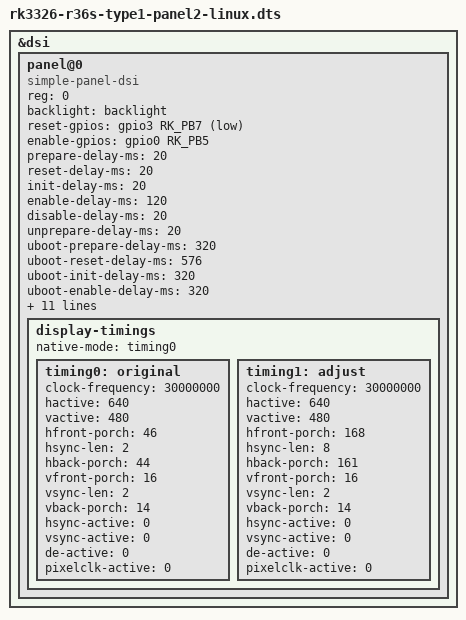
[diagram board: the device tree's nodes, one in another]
// SPDX-License-Identifier: (GPL-2.0+ OR MIT)
/*
* Copyright (c) 2025 kk&lcdyk
*
* R36S Clone掌机 种类1
*
*/

/dts-v1/;
#include "rk3326-r36s-type1-panel1-linux.dts"

&dsi {
	status = "okay";
	
	panel@0 {
		compatible = "simple-panel-dsi";
		reg = <0>;
		/* pwm1 backlight */
		backlight = <&backlight>;
		/* LCD reset gpio GPIO3.B7 */
		reset-gpios = <&gpio3 RK_PB7 GPIO_ACTIVE_LOW>;
		/* LCD reset gpio GPIO0.B5 */
		enable-gpios = <&gpio0 RK_PB5 GPIO_ACTIVE_HIGH>;
		prepare-delay-ms = <20>;
		reset-delay-ms = <20>;
		init-delay-ms = <20>;
		enable-delay-ms = <120>;
		disable-delay-ms = <20>;
		unprepare-delay-ms = <20>;
		uboot-prepare-delay-ms = <320>;
		uboot-reset-delay-ms = <576>;
		uboot-init-delay-ms = <320>;
		uboot-enable-delay-ms = <320>;
		uboot-disable-delay-ms = <320>;
		uboot-unprepare-delay-ms = <20>;
		width-mm = <153>;
		height-mm = <85>;
		dsi,flags  = <(MIPI_DSI_MODE_VIDEO |
		MIPI_DSI_MODE_VIDEO_BURST |
		MIPI_DSI_MODE_LPM |
		MIPI_DSI_MODE_EOT_PACKET)>;
		dsi,format = <MIPI_DSI_FMT_RGB888>;
		dsi,lanes = <4>;
		panel-init-sequence = [15 00 02 ff 30 15 00 02 ff 52 15 00 02 ff 01 15 00 02 e3 00 15 00 02 25 10 15 00 02 28 6f 15 00 02 29 01 15 00 02 2a df 15 00 02 2c 22 15 00 02 c3 0f 15 00 02 37 9c 15 00 02 38 a7 15 00 02 39 41 15 00 02 80 20 15 00 02 91 67 15 00 02 92 67 15 00 02 a0 55 15 00 02 a1 50 15 00 02 a3 58 15 00 02 a4 9c 15 00 02 a7 02 15 00 02 a8 01 15 00 02 a9 21 15 00 02 aa fc 15 00 02 ab 28 15 00 02 ac 06 15 00 02 ad 06 15 00 02 ae 06 15 00 02 af 03 15 00 02 b0 08 15 00 02 b1 26 15 00 02 b2 28 15 00 02 b3 28 15 00 02 b4 03 15 00 02 b5 08 15 00 02 b6 26 15 00 02 b7 08 15 00 02 b8 26 15 00 02 c0 00 15 00 02 c1 00 15 00 02 c2 00 15 00 02 ff 30 15 00 02 ff 52 15 00 02 ff 02 15 00 02 b0 02 15 00 02 d0 02 15 00 02 b1 0f 15 00 02 d1 10 15 00 02 b2 11 15 00 02 d2 12 15 00 02 b3 32 15 00 02 d3 33 15 00 02 b4 36 15 00 02 d4 36 15 00 02 b5 3c 15 00 02 d5 3c 15 00 02 b6 20 15 00 02 d6 20 15 00 02 b7 3e 15 00 02 d7 3e 15 00 02 b8 0e 15 00 02 d8 0d 15 00 02 b9 05 15 00 02 d9 05 15 00 02 ba 11 15 00 02 da 12 15 00 02 bb 11 15 00 02 db 11 15 00 02 bc 13 15 00 02 dc 14 15 00 02 bd 14 15 00 02 dd 14 15 00 02 be 16 15 00 02 de 18 15 00 02 bf 0e 15 00 02 df 0f 15 00 02 c0 17 15 00 02 e0 17 15 00 02 c1 07 15 00 02 e1 08 15 00 02 ff 30 15 00 02 ff 52 15 00 02 ff 03 15 00 02 08 8a 15 00 02 09 8b 15 00 02 30 00 15 00 02 31 00 15 00 02 32 00 15 00 02 33 00 15 00 02 34 61 15 00 02 35 d4 15 00 02 36 24 15 00 02 37 03 15 00 02 40 86 15 00 02 41 87 15 00 02 42 84 15 00 02 43 85 15 00 02 44 11 15 00 02 45 de 15 00 02 46 dd 15 00 02 47 11 15 00 02 48 e0 15 00 02 49 df 15 00 02 50 82 15 00 02 51 83 15 00 02 52 80 15 00 02 53 81 15 00 02 54 11 15 00 02 55 e2 15 00 02 56 e1 15 00 02 57 11 15 00 02 58 e4 15 00 02 59 e3 15 00 02 82 0f 15 00 02 83 0f 15 00 02 84 00 15 00 02 85 0f 15 00 02 86 0f 15 00 02 87 0e 15 00 02 88 0e 15 00 02 89 06 15 00 02 8a 06 15 00 02 8b 07 15 00 02 8c 07 15 00 02 8d 04 15 00 02 8e 04 15 00 02 8f 05 15 00 02 90 05 15 00 02 98 0f 15 00 02 99 0f 15 00 02 9a 00 15 00 02 9b 0f 15 00 02 9c 0f 15 00 02 9d 0e 15 00 02 9e 0e 15 00 02 9f 06 15 00 02 a0 06 15 00 02 a1 07 15 00 02 a2 07 15 00 02 a3 04 15 00 02 a4 04 15 00 02 a5 05 15 00 02 a6 05 15 00 02 e0 02 15 00 02 e1 52 15 00 02 ff 30 15 00 02 ff 52 15 00 02 ff 00 15 00 02 36 02 05 c8 01 11 05 64 01 29];
		panel-exit-sequence = <0x5000128 0x5000110>;
		
		display-timings {
			native-mode = <&timing0>;
			
			// 30.00MHz / (640+46+2+44)×(480+16+2+14) = 732×512 = 80.05 Hz
			timing0: original {
				clock-frequency = <30000000>;
				hactive = <640>;
				vactive = <480>;
				hfront-porch = <46>;
				hsync-len = <2>;
				hback-porch = <44>;
				vfront-porch = <16>;
				vsync-len = <2>;
				vback-porch = <14>;
				hsync-active = <0>;
				vsync-active = <0>;
				de-active = <0>;
				pixelclk-active = <0>;
			};
			
			// 30.00MHz / (640+168+8+161)×(480+16+2+14) = 977×512 = 59.97 Hz
			timing1: adjust {
				clock-frequency = <30000000>;
				hactive = <640>;
				vactive = <480>;
				hfront-porch = <168>;
				hsync-len = <8>;
				hback-porch = <161>;
				vfront-porch = <16>;
				vsync-len = <2>;
				vback-porch = <14>;
				hsync-active = <0>;
				vsync-active = <0>;
				de-active = <0>;
				pixelclk-active = <0>;
			};
		};
	};
};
